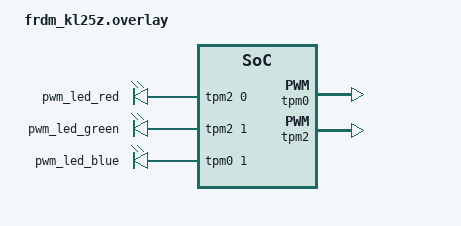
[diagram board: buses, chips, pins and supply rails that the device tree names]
#include <zephyr/dt-bindings/pwm/pwm.h>
#include <zephyr/dt-bindings/clock/kinetis_sim.h>

#include <nxp/kinetis/MKL25Z128VLK4-pinctrl.h>

/ {
    leds {
        status = "disabled";
    };
};

&pinctrl {
    tpm0_default: tpm0_default {
        group0 {
            pinmux = <TPM0_CH1_PTD1>;
            drive-strength = "low";
            slew-rate = "slow";
        };
    };

    tpm2_default: tpm2_default {
        group0 {
            pinmux = <TPM2_CH0_PTB18>,
                     <TPM2_CH1_PTB19>;
            drive-strength = "low";
            slew-rate = "slow";
        };
    };
};

/*
    f_pwm = f_core / (period * prescale),   f_core   = 48 MHz
                                            period   = 1000
                                            prescale = 128
    f_pwm = 48000000 / (1000 * 128) = 375 Hz > 60 Hz
*/
/ {
    soc {
        tpm0: pwm@40038000 {
            compatible = "nxp,kinetis-tpm";
            reg = <0x40038000 0x1000>;
            interrupts = <17 0>; 
            prescaler = <128>;
            
            clocks = <&sim KINETIS_SIM_BUS_CLK 0x103C 24>;
            
            pinctrl-0 = <&tpm0_default>;
            pinctrl-names = "default";
            #pwm-cells = <3>;
            status = "okay";
        };

        tpm2: pwm@4003a000 {
            compatible = "nxp,kinetis-tpm";
            reg = <0x4003a000 0x1000>;
            interrupts = <19 0>; 
            prescaler = <128>;
            
            clocks = <&sim KINETIS_SIM_BUS_CLK 0x103C 26>;
            
            pinctrl-0 = <&tpm2_default>;
            pinctrl-names = "default";
            #pwm-cells = <3>;
            status = "okay";
        };
    };
};

/ {
    aliases {
        pwm-led-red   = &pwm_led_red;
        pwm-led-green = &pwm_led_green;
        pwm-led-blue  = &pwm_led_blue;
    };

    pwmleds {
        compatible = "pwm-leds";
        
        pwm_led_red: pwm_led_red {
            pwms = <&tpm2 0 PWM_MSEC(1) PWM_POLARITY_INVERTED>;
        };
        
        pwm_led_green: pwm_led_green {
            pwms = <&tpm2 1 PWM_MSEC(1) PWM_POLARITY_INVERTED>;
        };
        
        pwm_led_blue: pwm_led_blue {
            pwms = <&tpm0 1 PWM_MSEC(1) PWM_POLARITY_INVERTED>;
        };
    };
};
